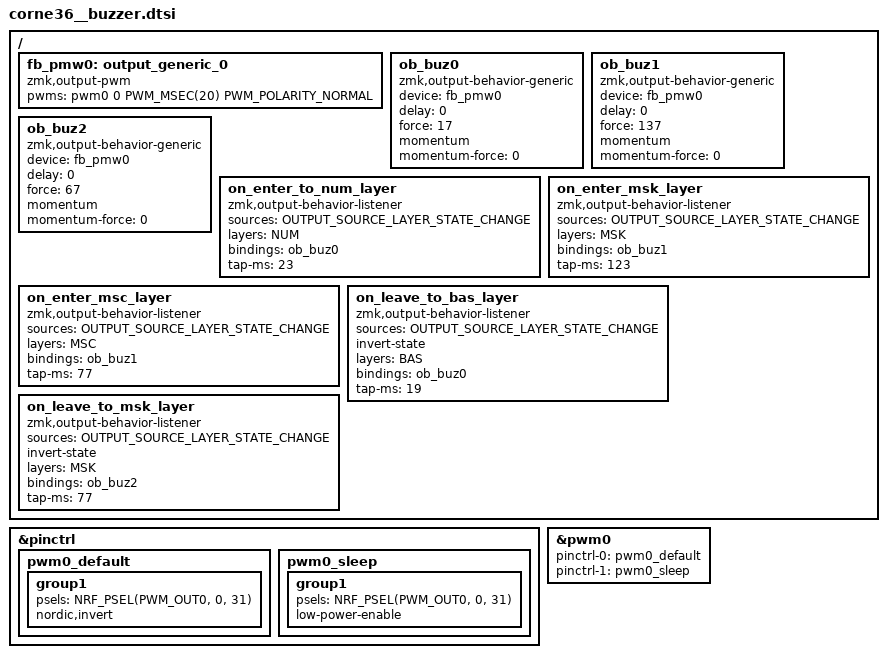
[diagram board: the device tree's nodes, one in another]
/*
 * Copyright (c) 2020 Pete Johanson
 *
 * SPDX-License-Identifier: MIT
 */

&pinctrl {
  pwm0_default: pwm0_default {
		group1 {
			psels = <NRF_PSEL(PWM_OUT0, 0, 31)>;
			nordic,invert;
		};
	};
	pwm0_sleep: pwm0_sleep {
		group1 {
			psels = <NRF_PSEL(PWM_OUT0, 0, 31)>;
			low-power-enable;
		};
	};
};
&pwm0 {
	status = "okay";
	pinctrl-0 = <&pwm0_default>;
	pinctrl-1 = <&pwm0_sleep>;
	pinctrl-names = "default", "sleep";
};
/{
	fb_pmw0: output_generic_0 {
		compatible = "zmk,output-pwm";
		#binding-cells = <0>;
		pwms = <&pwm0 0 PWM_MSEC(20) PWM_POLARITY_NORMAL>;
	};
	// output_relay_config_202 {
	// 	compatible = "zmk,split-peripheral-output-relay";
	// 	relay-channel = <202>;
	// 	device = <&fb_pmw0>;
	// };
};

#define BAS 0
#define GME 1
#define LNP 2
#define RNP 3
#define LHB 4
#define NUM 5
#define MSK 6
#define MSC 7

#define OUTPUT_SOURCE_LAYER_STATE_CHANGE        1
#define OUTPUT_SOURCE_POSITION_STATE_CHANGE     2
#define OUTPUT_SOURCE_KEYCODE_STATE_CHANGE      3
#define OUTPUT_SOURCE_MOUSE_BUTTON_STATE_CHANGE 4
#define OUTPUT_SOURCE_MOUSE_WHEEL_STATE_CHANGE  5
#define OUTPUT_SOURCE_TRANSPORT                 6
/{

	ob_buz0: ob_buz0 {
		compatible = "zmk,output-behavior-generic"; #binding-cells = <0>;
		device = <&fb_pmw0>; delay = <0>;
		force = <17>; momentum; momentum-force = <0>;
	};
	ob_buz1: ob_buz1 {
		compatible = "zmk,output-behavior-generic"; #binding-cells = <0>;
		device = <&fb_pmw0>; delay = <0>;
		force = <137>; momentum; momentum-force = <0>;
	};
	ob_buz2: ob_buz2 {
		compatible = "zmk,output-behavior-generic"; #binding-cells = <0>;
		device = <&fb_pmw0>; delay = <0>;
		force = <67>; momentum; momentum-force = <0>;
	};

	on_enter_to_num_layer {
		compatible = "zmk,output-behavior-listener";
		sources = < OUTPUT_SOURCE_LAYER_STATE_CHANGE >;
		layers = < NUM >; bindings = < &ob_buz0 >; tap-ms = <23>;
	};
	on_enter_msk_layer {
		compatible = "zmk,output-behavior-listener";
		sources = < OUTPUT_SOURCE_LAYER_STATE_CHANGE >;
		layers = < MSK >; bindings = < &ob_buz1 >; tap-ms = <123>;
	};
	on_enter_msc_layer {
		compatible = "zmk,output-behavior-listener";
		sources = < OUTPUT_SOURCE_LAYER_STATE_CHANGE >;
		layers = < MSC >; bindings = < &ob_buz1 >; tap-ms = <77>;
	};

	on_leave_to_bas_layer {
		compatible = "zmk,output-behavior-listener";
		sources = < OUTPUT_SOURCE_LAYER_STATE_CHANGE >;
		invert-state; layers = < BAS >; bindings = < &ob_buz0 >; tap-ms = <19>;
	};
	on_leave_to_msk_layer {
		compatible = "zmk,output-behavior-listener";
		sources = < OUTPUT_SOURCE_LAYER_STATE_CHANGE >;
		invert-state; layers = < MSK >; bindings = < &ob_buz2 >; tap-ms = <77>;
	};

};
